# STM32F415OGY6 register map
File version: 1.0
Registers are 32-bit, access not given, reset 0x0 unless marked. A register's access mark holds for its fields unless they carry their own. Offsets are from the block's base; [hi:lo] are bit positions; {n}, {i} and the like mark numbered series; 'fields as' and 'values as' point back to an identical list.

## DCMI
Base 0x50050000
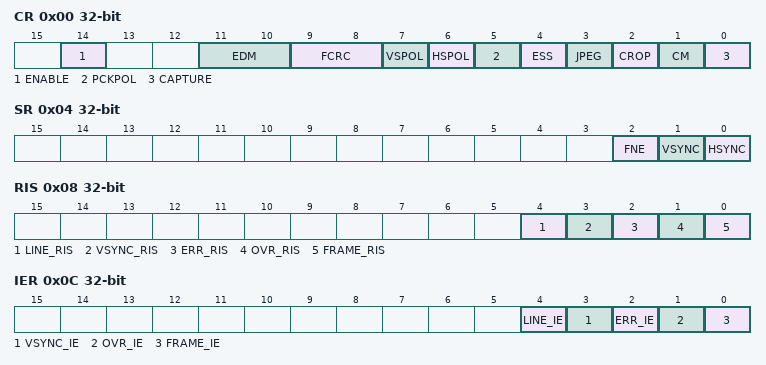
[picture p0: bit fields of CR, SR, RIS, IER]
0x00 CR
  [14] ENABLE, [11:10] EDM, [9:8] FCRC, [7] VSPOL, [6] HSPOL, [5] PCKPOL, [4] ESS, [3] JPEG, [2] CROP, [1] CM, [0] CAPTURE
0x04 SR
  [2] FNE, [1] VSYNC, [0] HSYNC
0x08 RIS
  [4] LINE_RIS, [3] VSYNC_RIS, [2] ERR_RIS, [1] OVR_RIS, [0] FRAME_RIS
0x0C IER
  [4] LINE_IE, [3] VSYNC_IE, [2] ERR_IE, [1] OVR_IE, [0] FRAME_IE
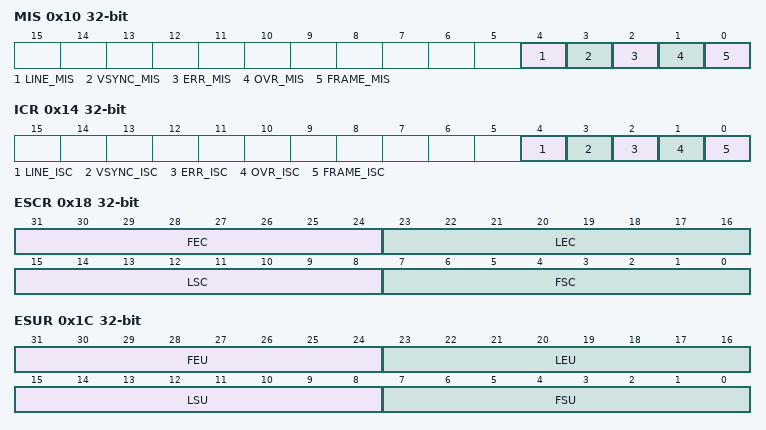
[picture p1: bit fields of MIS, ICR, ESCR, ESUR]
0x10 MIS
  [4] LINE_MIS, [3] VSYNC_MIS, [2] ERR_MIS, [1] OVR_MIS, [0] FRAME_MIS
0x14 ICR
  [4] LINE_ISC, [3] VSYNC_ISC, [2] ERR_ISC, [1] OVR_ISC, [0] FRAME_ISC
0x18 ESCR
  [31:24] FEC, [23:16] LEC, [15:8] LSC, [7:0] FSC
0x1C ESUR
  [31:24] FEU, [23:16] LEU, [15:8] LSU, [7:0] FSU
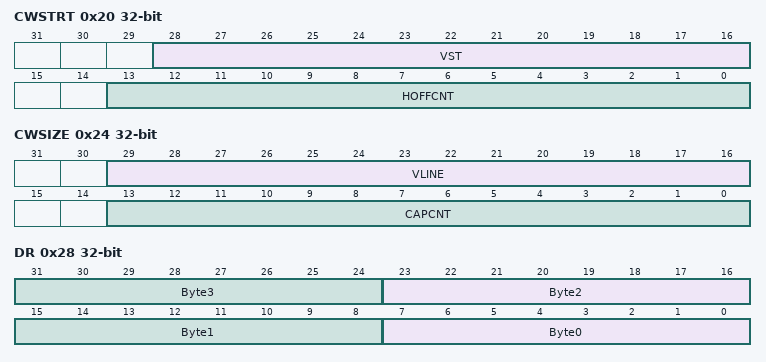
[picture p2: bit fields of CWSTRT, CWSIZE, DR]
0x20 CWSTRT
  [28:16] VST, [13:0] HOFFCNT
0x24 CWSIZE
  [29:16] VLINE, [13:0] CAPCNT
0x28 DR
  [8n+7:8n] Byte{n} (n=0..3)

## CRYP
Base 0x50060000
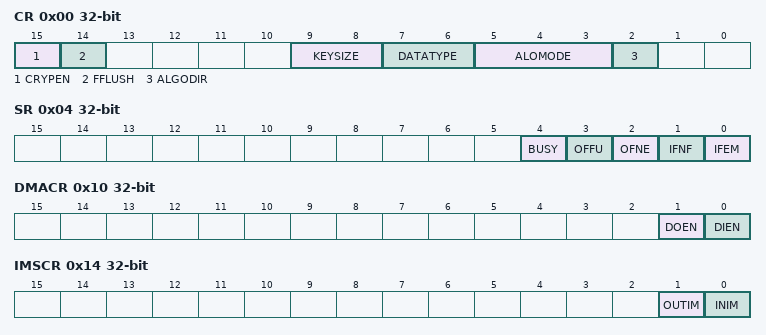
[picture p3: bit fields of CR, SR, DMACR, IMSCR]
0x00 CR
  [15] CRYPEN, [14] FFLUSH, [9:8] KEYSIZE, [7:6] DATATYPE, [5:3] ALOMODE, [2] ALGODIR
0x04 SR
  [4] BUSY, [3] OFFU, [2] OFNE, [1] IFNF, [0] IFEM
0x08 DIN
  [31:0] DATAIN
0x0C DOUT
  [31:0] DATAOUT
0x10 DMACR
  [1] DOEN, [0] DIEN
0x14 IMSCR
  [1] OUTIM, [0] INIM
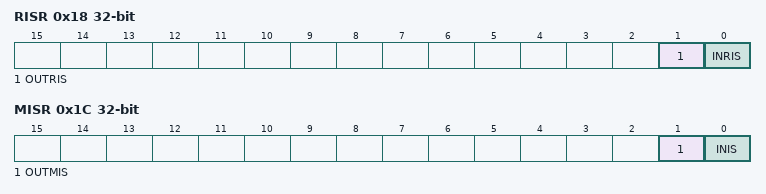
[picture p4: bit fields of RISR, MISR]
0x18 RISR
  [1] OUTRIS, [0] INRIS
0x1C MISR
  [1] OUTMIS, [0] INIS
0x20 K0LR
  [31:0] CRYP_K0LR
0x24 K0RR
  [31:0] CRYP_K0RR
0x38 K3LR
  [31:0] CRYP_K3LR
0x3C K3RR
  [31:0] CRYP_K3RR
0x40 IV0LR
  [31:0] CRYP_IV0LR
0x44 IV0RR
  [31:0] CRYP_IV0RR
0x48 IV1LR
  [31:0] CRYP_IV1LR
0x4C IV1RR
  [31:0] CRYP_IV1RR

## HASH
Base 0x50060400
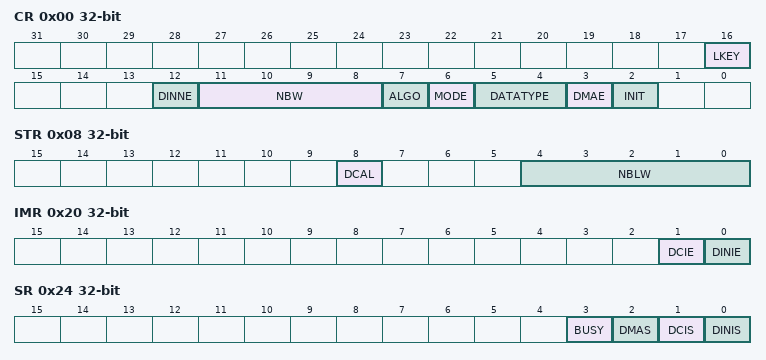
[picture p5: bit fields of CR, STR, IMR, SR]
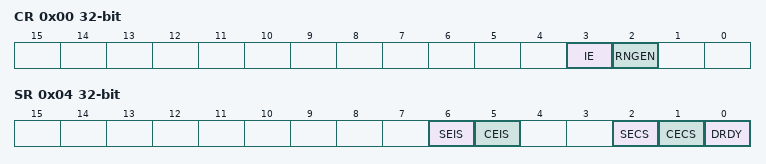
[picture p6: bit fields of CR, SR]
0x00 CR
  [16] LKEY, [12] DINNE, [11:8] NBW, [7] ALGO, [6] MODE, [5:4] DATATYPE, [3] DMAE, [2] INIT
0x04 DIN
  [31:0] DATAIN
0x08 STR
  [8] DCAL, [4:0] NBLW
0x20 IMR
  [1] DCIE, [0] DINIE
0x24 SR
  [3] BUSY, [2] DMAS, [1] DCIS, [0] DINIS
0xF8 CSR0
0x1C0 CSR50
{0x310+4i} HR{i} (i=0..4)
  [31:0] H{i}

## RNG
Base 0x50060800
0x00 CR
  [3] IE, [2] RNGEN
0x04 SR
  [6] SEIS, [5] CEIS, [2] SECS, [1] CECS, [0] DRDY
0x08 DR
  [31:0] RNDATA

## FSMC
Base 0xA0000000
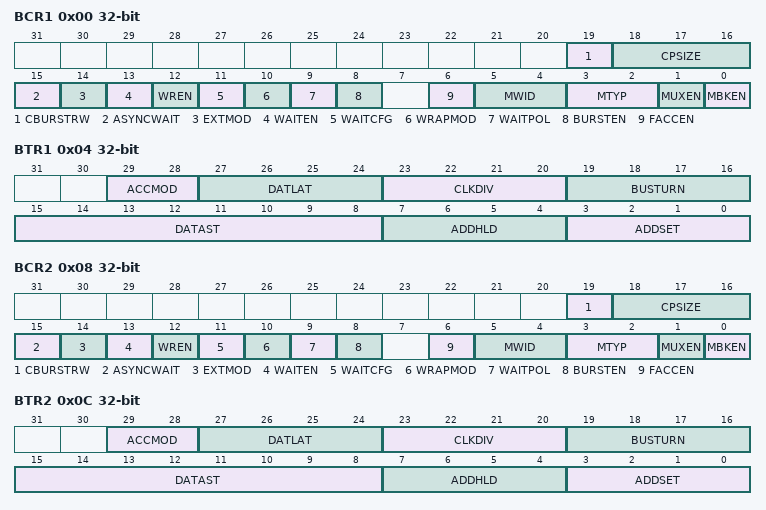
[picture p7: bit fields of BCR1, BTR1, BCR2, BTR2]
0x00 BCR1
  [19] CBURSTRW, [18:16] CPSIZE, [15] ASYNCWAIT, [14] EXTMOD, [13] WAITEN, [12] WREN, [11] WAITCFG, [10] WRAPMOD, [9] WAITPOL, [8] BURSTEN, [6] FACCEN, [5:4] MWID, [3:2] MTYP, [1] MUXEN, [0] MBKEN
0x04 BTR1
  [29:28] ACCMOD, [27:24] DATLAT, [23:20] CLKDIV, [19:16] BUSTURN, [15:8] DATAST, [7:4] ADDHLD, [3:0] ADDSET
0x08 BCR2
  fields as BCR1
0x0C BTR2
  fields as BTR1
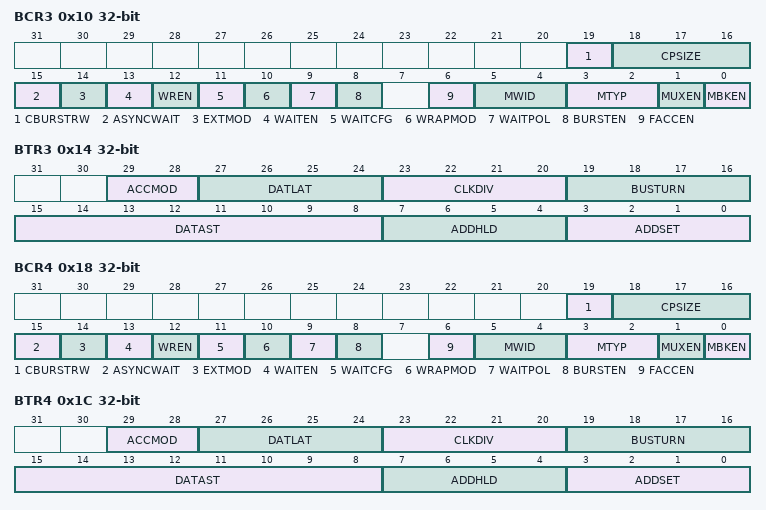
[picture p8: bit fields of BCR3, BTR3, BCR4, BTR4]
0x10 BCR3
  fields as BCR1
0x14 BTR3
  fields as BTR1
0x18 BCR4
  fields as BCR1
0x1C BTR4
  fields as BTR1
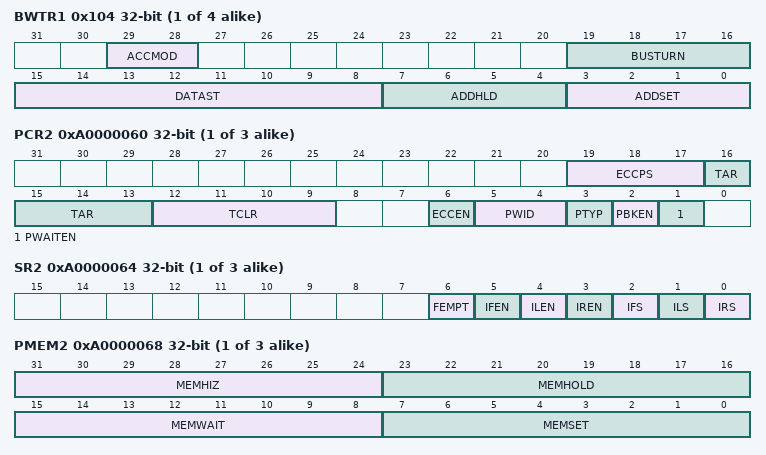
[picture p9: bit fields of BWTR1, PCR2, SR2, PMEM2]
{0xFC+8i} BWTR{i} (i=1..4)
  [29:28] ACCMOD, [19:16] BUSTURN, [15:8] DATAST, [7:4] ADDHLD, [3:0] ADDSET
{0xA0000020+0x20*i} PCR{i} (i=2..4)
  [19:17] ECCPS, [16:13] TAR, [12:9] TCLR, [6] ECCEN, [5:4] PWID, [3] PTYP, [2] PBKEN, [1] PWAITEN
{0xA0000024+0x20*i} SR{i} (i=2..4)
  [6] FEMPT, [5] IFEN, [4] ILEN, [3] IREN, [2] IFS, [1] ILS, [0] IRS
{0xA0000028+0x20*i} PMEM{i} (i=2..4)
  [31:24] MEMHIZ, [23:16] MEMHOLD, [15:8] MEMWAIT, [7:0] MEMSET
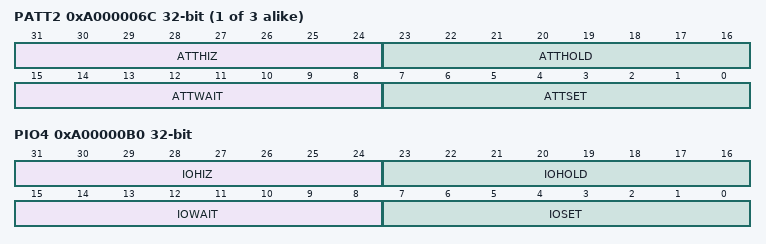
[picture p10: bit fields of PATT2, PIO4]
{0xA000002C+0x20*i} PATT{i} (i=2..4)
  [31:24] ATTHIZ, [23:16] ATTHOLD, [15:8] ATTWAIT, [7:0] ATTSET
0xA0000074 ECCR2
  [31:0] ECC
0xA0000094 ECCR3
  [31:0] ECC
0xA00000B0 PIO4
  [31:24] IOHIZ, [23:16] IOHOLD, [15:8] IOWAIT, [7:0] IOSET

## FMC
Base 0xA0000000
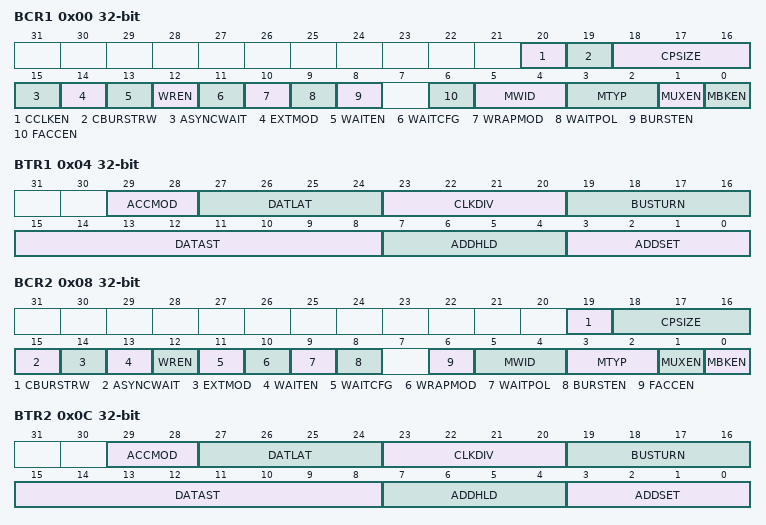
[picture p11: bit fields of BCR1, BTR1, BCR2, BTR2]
0x00 BCR1
  [20] CCLKEN, [19] CBURSTRW, [18:16] CPSIZE, [15] ASYNCWAIT, [14] EXTMOD, [13] WAITEN, [12] WREN, [11] WAITCFG, [10] WRAPMOD, [9] WAITPOL, [8] BURSTEN, [6] FACCEN, [5:4] MWID, [3:2] MTYP, [1] MUXEN, [0] MBKEN
0x04 BTR1
  [29:28] ACCMOD, [27:24] DATLAT, [23:20] CLKDIV, [19:16] BUSTURN, [15:8] DATAST, [7:4] ADDHLD, [3:0] ADDSET
0x08 BCR2
  [19] CBURSTRW, [18:16] CPSIZE, [15] ASYNCWAIT, [14] EXTMOD, [13] WAITEN, [12] WREN, [11] WAITCFG, [10] WRAPMOD, [9] WAITPOL, [8] BURSTEN, [6] FACCEN, [5:4] MWID, [3:2] MTYP, [1] MUXEN, [0] MBKEN
0x0C BTR2
  fields as BTR1
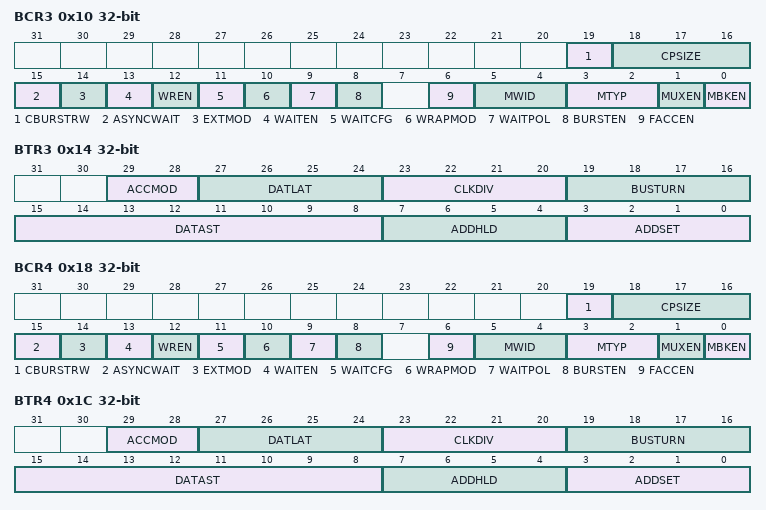
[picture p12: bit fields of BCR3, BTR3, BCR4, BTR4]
0x10 BCR3
  fields as BCR2
0x14 BTR3
  fields as BTR1
0x18 BCR4
  fields as BCR2
0x1C BTR4
  fields as BTR1
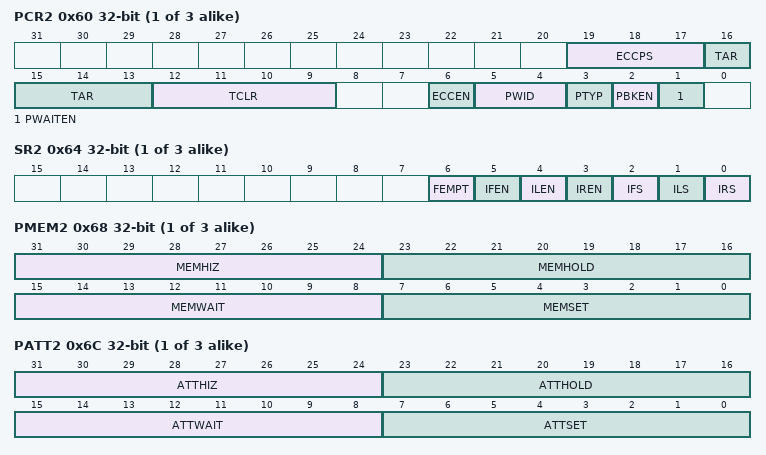
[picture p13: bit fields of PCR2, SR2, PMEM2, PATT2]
{0x20+0x20*i} PCR{i} (i=2..4)
  [19:17] ECCPS, [16:13] TAR, [12:9] TCLR, [6] ECCEN, [5:4] PWID, [3] PTYP, [2] PBKEN, [1] PWAITEN
{0x24+0x20*i} SR{i} (i=2..4)
  [6] FEMPT, [5] IFEN, [4] ILEN, [3] IREN, [2] IFS, [1] ILS, [0] IRS
{0x28+0x20*i} PMEM{i} (i=2..4)
  [31:24] MEMHIZ, [23:16] MEMHOLD, [15:8] MEMWAIT, [7:0] MEMSET
{0x2C+0x20*i} PATT{i} (i=2..4)
  [31:24] ATTHIZ, [23:16] ATTHOLD, [15:8] ATTWAIT, [7:0] ATTSET
0x74 ECCR2
  [31:0] ECC
0x94 ECCR3
  [31:0] ECC
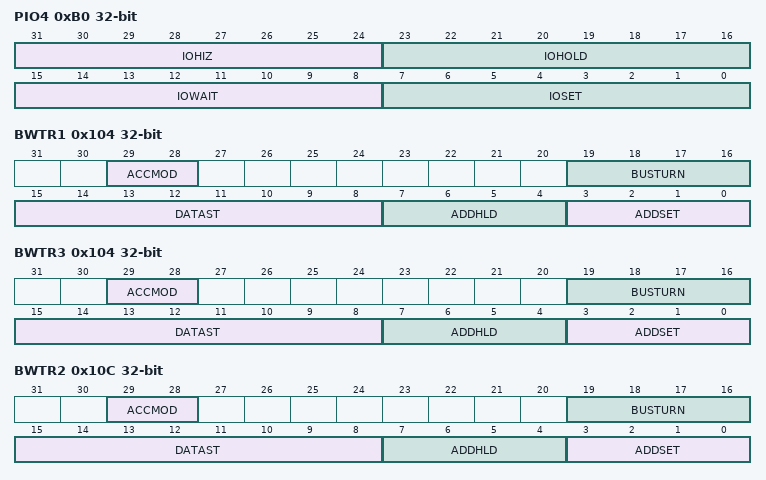
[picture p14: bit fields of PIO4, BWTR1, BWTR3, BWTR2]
0xB0 PIO4
  [31:24] IOHIZ, [23:16] IOHOLD, [15:8] IOWAIT, [7:0] IOSET
0x104 BWTR1
  [29:28] ACCMOD, [19:16] BUSTURN, [15:8] DATAST, [7:4] ADDHLD, [3:0] ADDSET
0x104 BWTR3
  fields as BWTR1
0x10C BWTR2
  fields as BWTR1
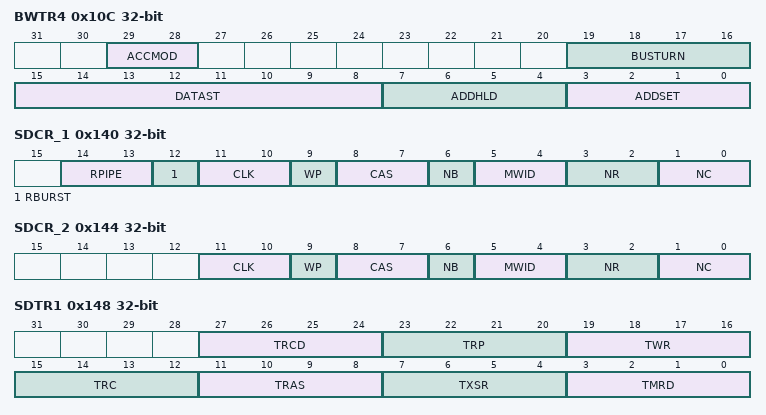
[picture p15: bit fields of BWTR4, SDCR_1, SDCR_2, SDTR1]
0x10C BWTR4
  fields as BWTR1
0x140 SDCR_1
  [14:13] RPIPE, [12] RBURST, [11:10] CLK, [9] WP, [8:7] CAS, [6] NB, [5:4] MWID, [3:2] NR, [1:0] NC
0x144 SDCR_2
  [11:10] CLK, [9] WP, [8:7] CAS, [6] NB, [5:4] MWID, [3:2] NR, [1:0] NC
0x148 SDTR1
  [27:24] TRCD, [23:20] TRP, [19:16] TWR, [15:12] TRC, [11:8] TRAS, [7:4] TXSR, [3:0] TMRD
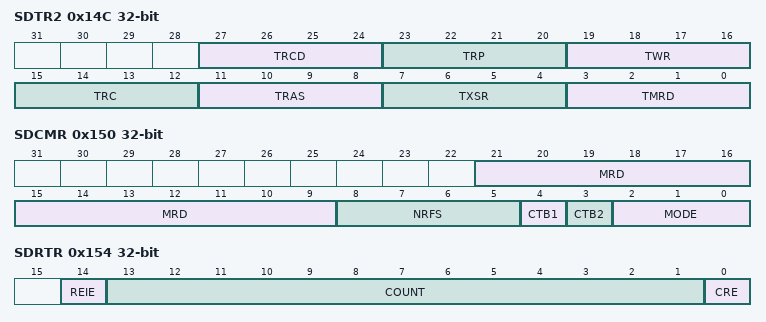
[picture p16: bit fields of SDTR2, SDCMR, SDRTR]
0x14C SDTR2
  fields as SDTR1
0x150 SDCMR
  [21:9] MRD, [8:5] NRFS, [4] CTB1, [3] CTB2, [2:0] MODE
0x154 SDRTR
  [14] REIE, [13:1] COUNT, [0] CRE
0x158 SDSR
  [5] BUSY, [4:3] MODES2, [2:1] MODES1, [0] RE
